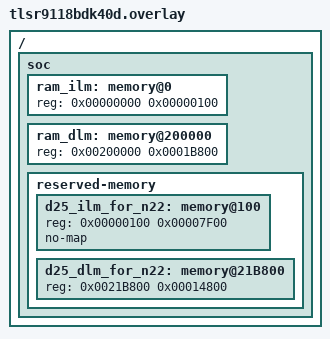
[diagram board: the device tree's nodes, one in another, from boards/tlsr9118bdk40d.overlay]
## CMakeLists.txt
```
# SPDX-License-Identifier: Apache-2.0

cmake_minimum_required(VERSION 3.20.0)
find_package(Zephyr REQUIRED HINTS $ENV{ZEPHYR_BASE})
project(opus)

if (NOT CONFIG_SOC_RISCV_TELINK_W91)
  message(FATAL_ERROR "SOC is not supported for this sample")
endif()

target_sources(app PRIVATE
	src/main.c
)
```

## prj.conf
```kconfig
CONFIG_TELINK_OPUS_REMOTE=y
CONFIG_LOG=y
CONFIG_LOG_MODE_MINIMAL=y
CONFIG_PBUF_RX_READ_BUF_SIZE=9000

# INFO log level by default, uncomment if DEBUG needed:
# CONFIG_TELINK_OPUS_REMOTE_LOG_LEVEL_DEBG=y
```

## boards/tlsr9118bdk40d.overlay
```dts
/*
 * Copyright (c) 2025 Telink Semiconductor
 *
 * SPDX-License-Identifier: Apache-2.0
 */

/ {
	soc {
		ram_ilm: memory@0 {
			reg = <0x00000000 0x00000100>;
		};

		ram_dlm: memory@200000 {
			reg = <0x00200000 0x0001B800>;
		};

		reserved-memory {
			/* 32,5 KB for N22 */
			d25_ilm_for_n22: memory@100 {
				reg = <0x00000100 0x00007F00>;
				no-map;
			};

			/* remaining ~82 KB for N22 */
			d25_dlm_for_n22: memory@21B800 {
				reg = <0x0021B800 0x00014800>;
			};
		};
	};
};
```

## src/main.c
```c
/*
 * Copyright (c) 2025 Telink Semiconductor
 *
 * SPDX-License-Identifier: Apache-2.0
 */

#include <zephyr/logging/log.h>
LOG_MODULE_REGISTER(main, LOG_LEVEL_INF);

int main(void)
{
	LOG_INF("***** Telink OPUS demo *****");

	return 0;
}
```
